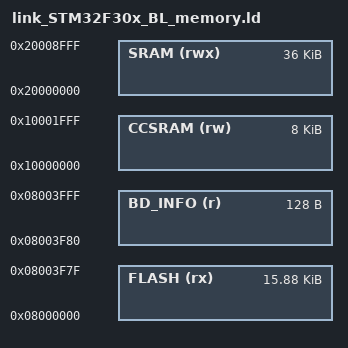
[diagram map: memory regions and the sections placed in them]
MEMORY
{
    FLASH (rx)    : ORIGIN = 0x08000000,        LENGTH = 0x004000 - 0x000080
    BD_INFO (r)   : ORIGIN = 0x08004000 - 0x80, LENGTH =            0x000080
    SRAM (rwx)    : ORIGIN = 0x20000000,        LENGTH = 0x009000
    CCSRAM (rw)   : ORIGIN = 0x10000000,        LENGTH = 0x002000
}
